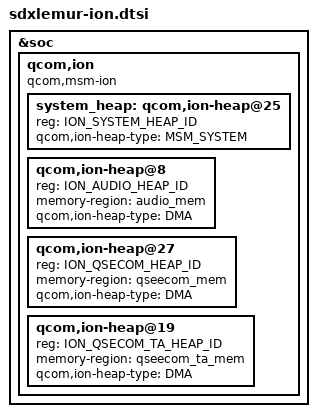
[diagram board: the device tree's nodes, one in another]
#include <dt-bindings/arm/msm/msm_ion_ids.h>

&soc {
	qcom,ion {
		compatible = "qcom,msm-ion";
		#address-cells = <1>;
		#size-cells = <0>;

		system_heap: qcom,ion-heap@25 {
			reg = <ION_SYSTEM_HEAP_ID>;
			qcom,ion-heap-type = "MSM_SYSTEM";
		};

		qcom,ion-heap@8 { /* AUDIO HEAP */
			reg = <ION_AUDIO_HEAP_ID>;
			memory-region = <&audio_mem>;
			qcom,ion-heap-type = "DMA";
		};

		qcom,ion-heap@27 { /* QSEECOM HEAP */
			reg = <ION_QSECOM_HEAP_ID>;
			memory-region = <&qseecom_mem>;
			qcom,ion-heap-type = "DMA";
		};

		qcom,ion-heap@19 { /* QSEECOM TA HEAP */
			reg = <ION_QSECOM_TA_HEAP_ID>;
			memory-region = <&qseecom_ta_mem>;
			qcom,ion-heap-type = "DMA";
		};
	};
};

